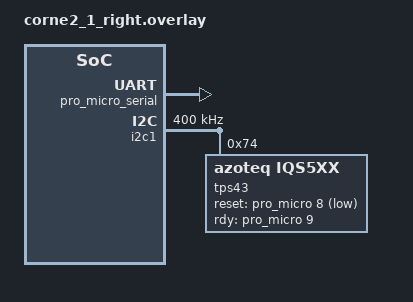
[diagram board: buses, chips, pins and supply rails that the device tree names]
/*
 * Copyright (c) 2026 Converted from swept by Copilot
 * SPDX-License-Identifier: MIT
 */

#include "corne2_1.dtsi"

&default_transform {
    col-offset = <6>;
};

&kscan0 {
    col-gpios
        = <&pro_micro 14 GPIO_ACTIVE_HIGH>
        , <&pro_micro 15 GPIO_ACTIVE_HIGH>
        , <&pro_micro 18 GPIO_ACTIVE_HIGH>
        , <&pro_micro 19 GPIO_ACTIVE_HIGH>
        , <&pro_micro 20 GPIO_ACTIVE_HIGH>
        , <&pro_micro 21 GPIO_ACTIVE_HIGH>
        ;
};

/* Habilita a UART no lado direito para o split com fio */
&pro_micro_serial {
    status = "okay";
};

/* Mapeia o trackpad no barramento I2C1 (GPIO 2 e GPIO 3) */
&i2c1 {
    status = "okay";
    pinctrl-0 = <&i2c1_default>;
    pinctrl-names = "default";
    clock-frequency = <400000>;

    tps43: iqs5xx@74 {
        status = "okay";
        compatible = "azoteq,iqs5xx";
        reg = <0x74>;

        /* Alterado para os pinos 8 e 9 para NAO conflitar com a UART (pinos 0 e 1) */
        reset-gpios = <&pro_micro 8 GPIO_ACTIVE_LOW>;
        rdy-gpios   = <&pro_micro 9 (GPIO_ACTIVE_HIGH | GPIO_PULL_DOWN)>;

        one-finger-tap;
        press-and-hold;
        press-and-hold-time = <180>;
        two-finger-tap;

        scroll;

        bottom-beta = <25>;
        stationary-threshold = <5>;

        switch-xy;
    };
};

&tps43_split {
    device = <&tps43>;
};
